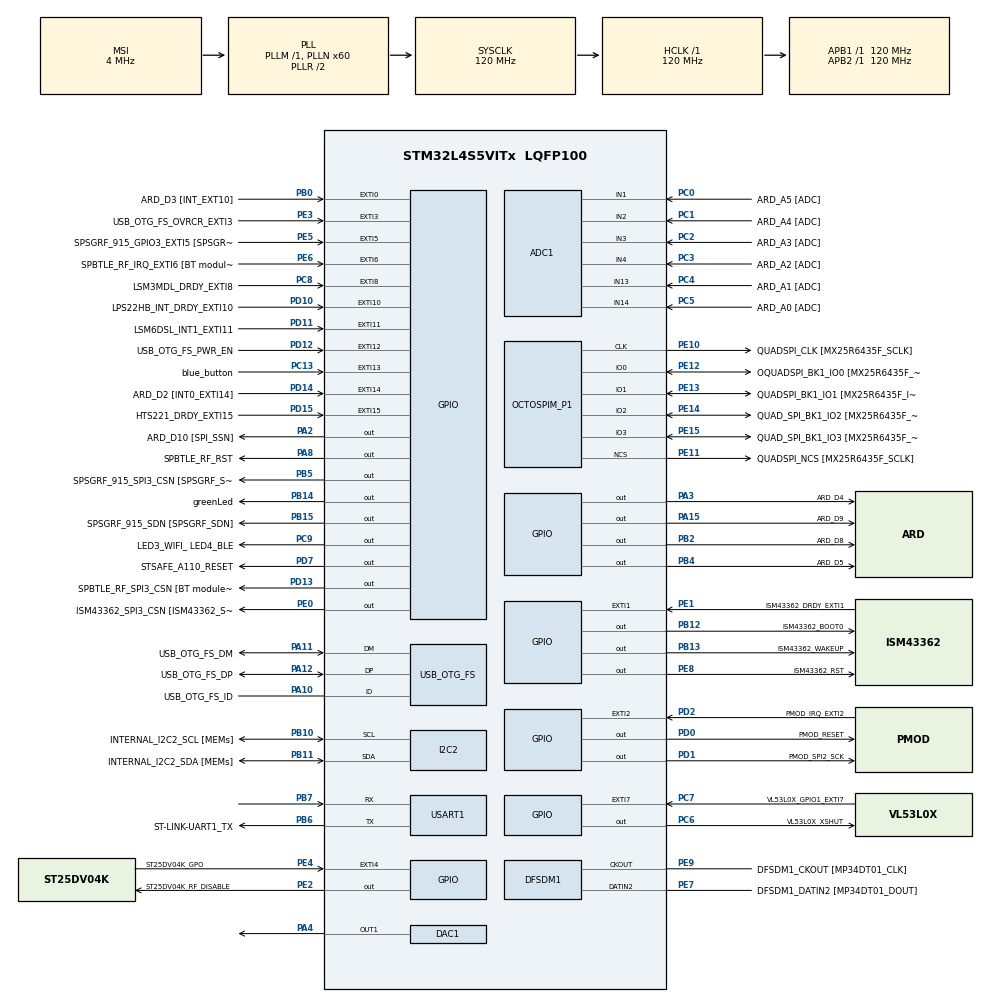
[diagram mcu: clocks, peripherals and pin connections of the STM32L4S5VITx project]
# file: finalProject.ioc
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ADC1.Channel-0\#ChannelRegularConversion=ADC_CHANNEL_1
ADC1.NbrOfConversionFlag=1
ADC1.OffsetNumber-0\#ChannelRegularConversion=ADC_OFFSET_NONE
ADC1.Rank-0\#ChannelRegularConversion=1
ADC1.SamplingTime-0\#ChannelRegularConversion=ADC_SAMPLETIME_2CYCLES_5
ADC1.master=1
DAC1.DAC_Trigger-DAC_OUT1=DAC_TRIGGER_T2_TRGO
Dma.DAC1_CH1.0.Direction=DMA_MEMORY_TO_PERIPH
Dma.DAC1_CH1.0.EventEnable=DISABLE
Dma.DAC1_CH1.0.Instance=DMA1_Channel1
Dma.DAC1_CH1.0.MemDataAlignment=DMA_MDATAALIGN_WORD
Dma.DAC1_CH1.0.MemInc=DMA_MINC_ENABLE
Dma.DAC1_CH1.0.Mode=DMA_CIRCULAR
Dma.DAC1_CH1.0.PeriphDataAlignment=DMA_PDATAALIGN_HALFWORD
Dma.DAC1_CH1.0.PeriphInc=DMA_PINC_DISABLE
Dma.DAC1_CH1.0.Polarity=HAL_DMAMUX_REQUEST_GEN_RISING
Dma.DAC1_CH1.0.Priority=DMA_PRIORITY_LOW
Dma.DAC1_CH1.0.RequestNumber=1
Dma.DAC1_CH1.0.SignalID=NONE
Dma.DAC1_CH1.0.SyncEnable=DISABLE
Dma.DAC1_CH1.0.SyncPolarity=HAL_DMAMUX_SYNC_NO_EVENT
Dma.DAC1_CH1.0.SyncRequestNumber=1
Dma.DAC1_CH1.0.SyncSignalID=NONE
Dma.Request0=DAC1_CH1
I2C2.Timing=0x30A175AB
Mcu.Family=STM32L4
Mcu.Name=STM32L4S5VITx
Mcu.Package=LQFP100
NVIC.DMA1_Channel1_IRQn=true\:0\:0\:false\:false\:true\:false\:true\:true
NVIC.EXTI15_10_IRQn=true\:0\:0\:false\:false\:true\:true\:true\:true
NVIC.EXTI9_5_IRQn=true\:0\:0\:false\:false\:true\:true\:true\:true
NVIC.PriorityGroup=NVIC_PRIORITYGROUP_4
OCTOSPI1.MemoryType=HAL_OSPI_MEMTYPE_MACRONIX
PA0.GPIO_Label=ARD_D1 [UART4_TX]
PA0.GPIO_ModeDefaultPP=GPIO_MODE_AF_PP
PA0.GPIO_PuPd=GPIO_NOPULL
PA0.GPIO_Speed=GPIO_SPEED_FREQ_VERY_HIGH
PA0.Signal=UART4_TX
PA1.GPIO_Label=ARD_D0 [UART4_RX]
PA1.GPIO_ModeDefaultPP=GPIO_MODE_AF_PP
PA1.GPIO_PuPd=GPIO_NOPULL
PA1.GPIO_Speed=GPIO_SPEED_FREQ_VERY_HIGH
PA1.Signal=UART4_RX
PA10.GPIO_Label=USB_OTG_FS_ID
PA10.Mode=OTG/Dual_Role_Device
PA10.Signal=USB_OTG_FS_ID
PA11.GPIO_Label=USB_OTG_FS_DM
PA11.Mode=OTG/Dual_Role_Device
PA11.Signal=USB_OTG_FS_DM
PA12.GPIO_Label=USB_OTG_FS_DP
PA12.Mode=OTG/Dual_Role_Device
PA12.Signal=USB_OTG_FS_DP
PA13\ (JTMS/SWDIO).GPIO_Label=SYS_JTMS_SWDIO
PA13\ (JTMS/SWDIO).Mode=Serial_Wire
PA13\ (JTMS/SWDIO).Signal=SYS_JTMS-SWDIO
PA14\ (JTCK/SWCLK).GPIO_Label=SYS_JTCK_SWCLK
PA14\ (JTCK/SWCLK).Mode=Serial_Wire
PA14\ (JTCK/SWCLK).Signal=SYS_JTCK-SWCLK
PA15\ (JTDI).GPIO_Label=ARD_D9
PA15\ (JTDI).GPIO_ModeDefaultOutputPP=GPIO_MODE_OUTPUT_PP
PA15\ (JTDI).GPIO_PuPd=GPIO_NOPULL
PA15\ (JTDI).GPIO_Speed=GPIO_SPEED_FREQ_LOW
PA15\ (JTDI).PinState=GPIO_PIN_RESET
PA15\ (JTDI).Signal=GPIO_Output
PA2.GPIO_Label=ARD_D10 [SPI_SSN]
PA2.GPIO_ModeDefaultOutputPP=GPIO_MODE_OUTPUT_PP
PA2.GPIO_PuPd=GPIO_NOPULL
PA2.GPIO_Speed=GPIO_SPEED_FREQ_LOW
PA2.PinState=GPIO_PIN_RESET
PA2.Signal=GPIO_Output
PA3.GPIO_Label=ARD_D4
PA3.Signal=GPIO_Output
PA4.Signal=COMP_DAC11_group
PA5.GPIO_Label=ARD_D13 [SPI1_SCK/LED1]
PA5.GPIO_Mode=GPIO_MODE_AF_PP
PA5.GPIO_PuPd=GPIO_NOPULL
PA5.GPIO_Speed=GPIO_SPEED_FREQ_VERY_HIGH
PA5.Signal=SPI1_SCK
PA6.GPIO_Label=ARD_D12 [SPI1_MISO]
PA6.GPIO_Mode=GPIO_MODE_AF_PP
PA6.GPIO_PuPd=GPIO_NOPULL
PA6.GPIO_Speed=GPIO_SPEED_FREQ_VERY_HIGH
PA6.Signal=SPI1_MISO
PA7.GPIO_Label=ARD_D11 [SPI1_MOSI]
PA7.GPIO_Mode=GPIO_MODE_AF_PP
PA7.GPIO_PuPd=GPIO_NOPULL
PA7.GPIO_Speed=GPIO_SPEED_FREQ_VERY_HIGH
PA7.Signal=SPI1_MOSI
PA8.GPIO_Label=SPBTLE_RF_RST
PA8.GPIO_ModeDefaultOutputPP=GPIO_MODE_OUTPUT_PP
PA8.GPIO_PuPd=GPIO_NOPULL
PA8.GPIO_Speed=GPIO_SPEED_FREQ_LOW
PA8.PinState=GPIO_PIN_RESET
PA8.Signal=GPIO_Output
PB0.GPIO_Label=ARD_D3 [INT_EXT10]
PB0.GPIO_ModeDefaultEXTI=GPIO_MODE_IT_RISING
PB0.GPIO_PuPd=GPIO_NOPULL
PB0.Signal=GPXTI0
PB1.GPIO_Label=ARD_D6
PB1.GPIO_Speed=GPIO_SPEED_FREQ_LOW
PB1.Signal=S_TIM3_CH4
PB10.GPIO_Label=INTERNAL_I2C2_SCL [MEMs]
PB10.GPIO_Mode=GPIO_MODE_AF_OD
PB10.GPIO_Pu=GPIO_PULLUP
PB10.GPIO_Speed=GPIO_SPEED_FREQ_VERY_HIGH
PB10.Mode=I2C
PB10.Signal=I2C2_SCL
PB11.GPIO_Label=INTERNAL_I2C2_SDA [MEMs]
PB11.GPIO_Mode=GPIO_MODE_AF_OD
PB11.GPIO_Pu=GPIO_PULLUP
PB11.GPIO_Speed=GPIO_SPEED_FREQ_VERY_HIGH
PB11.Mode=I2C
PB11.Signal=I2C2_SDA
PB12.GPIO_Label=ISM43362_BOOT0
PB12.GPIO_ModeDefaultOutputPP=GPIO_MODE_OUTPUT_PP
PB12.GPIO_PuPd=GPIO_NOPULL
PB12.GPIO_Speed=GPIO_SPEED_FREQ_LOW
PB12.PinState=GPIO_PIN_RESET
PB12.Signal=GPIO_Output
PB13.GPIO_Label=ISM43362_WAKEUP
PB13.GPIO_ModeDefaultOutputPP=GPIO_MODE_OUTPUT_PP
PB13.GPIO_PuPd=GPIO_NOPULL
PB13.GPIO_Speed=GPIO_SPEED_FREQ_LOW
PB13.PinState=GPIO_PIN_RESET
PB13.Signal=GPIO_Output
PB14.GPIO_Label=greenLed
PB14.GPIO_ModeDefaultOutputPP=GPIO_MODE_OUTPUT_PP
PB14.GPIO_PuPd=GPIO_NOPULL
PB14.GPIO_Speed=GPIO_SPEED_FREQ_LOW
PB14.PinState=GPIO_PIN_RESET
PB14.Signal=GPIO_Output
PB15.GPIO_Label=SPSGRF_915_SDN [SPSGRF_SDN]
PB15.Signal=GPIO_Output
PB2.GPIO_Label=ARD_D8
PB2.GPIO_ModeDefaultOutputPP=GPIO_MODE_OUTPUT_PP
PB2.GPIO_PuPd=GPIO_NOPULL
PB2.GPIO_Speed=GPIO_SPEED_FREQ_LOW
PB2.PinState=GPIO_PIN_RESET
PB2.Signal=GPIO_Output
PB3\ (JTDO/TRACESWO).GPIO_Label=SYS_JTD0_SWO
PB3\ (JTDO/TRACESWO).Signal=SYS_JTDO-SWO
PB4\ (NJTRST).GPIO_Label=ARD_D5
PB4\ (NJTRST).GPIO_ModeDefaultOutputPP=GPIO_MODE_OUTPUT_PP
PB4\ (NJTRST).GPIO_PuPd=GPIO_NOPULL
PB4\ (NJTRST).GPIO_Speed=GPIO_SPEED_FREQ_LOW
PB4\ (NJTRST).PinState=GPIO_PIN_RESET
PB4\ (NJTRST).Signal=GPIO_Output
PB5.GPIO_Label=SPSGRF_915_SPI3_CSN [SPSGRF_SPI_CS]
PB5.Signal=GPIO_Output
PB6.GPIO_FM6=__NULL
PB6.GPIO_Label=ST-LINK-UART1_TX
PB6.GPIO_ModeDefaultPP=GPIO_MODE_AF_PP
PB6.GPIO_PuPd=GPIO_NOPULL
PB6.GPIO_Speed=GPIO_SPEED_FREQ_VERY_HIGH
PB6.Mode=Asynchronous
PB6.Signal=USART1_TX
PB7.Mode=Asynchronous
PB7.Signal=USART1_RX
PB8.GPIO_FM8=__NULL
PB8.GPIO_Label=ARD_D15 [I2C1_SCL]
PB8.GPIO_Mode=GPIO_MODE_AF_OD
PB8.GPIO_Pu=GPIO_PULLUP
PB8.GPIO_Speed=GPIO_SPEED_FREQ_VERY_HIGH
PB8.Signal=I2C1_SCL
PB9.GPIO_FM9=__NULL
PB9.GPIO_Label=ARD_D14 [I2C1_SDA]
PB9.GPIO_Mode=GPIO_MODE_AF_OD
PB9.GPIO_Pu=GPIO_PULLUP
PB9.GPIO_Speed=GPIO_SPEED_FREQ_VERY_HIGH
PB9.Signal=I2C1_SDA
PC0.GPIO_Label=ARD_A5 [ADC]
PC0.GPIO_Mode=GPIO_MODE_ANALOG_ADC_CONTROL
PC0.GPIO_PuPd=GPIO_NOPULL
PC0.Signal=ADCx_IN1
PC1.GPIO_Label=ARD_A4 [ADC]
PC1.GPIO_Mode=GPIO_MODE_ANALOG_ADC_CONTROL
PC1.GPIO_PuPd=GPIO_NOPULL
PC1.Signal=ADCx_IN2
PC10.GPIO_Label=INTERNAL-SPI3_SCK [BT module_SPI_MOSI] [ISM43362_MOSI]
PC10.GPIO_Mode=GPIO_MODE_AF_PP
PC10.GPIO_PuPd=GPIO_NOPULL
PC10.GPIO_Speed=GPIO_SPEED_FREQ_VERY_HIGH
PC10.Signal=SPI3_SCK
PC11.GPIO_Label=INTERNAL_SPI3_MISO [BT module_SPI_MOSI] [ISM43362_MOSI]
PC11.GPIO_Mode=GPIO_MODE_AF_PP
PC11.GPIO_PuPd=GPIO_NOPULL
PC11.GPIO_Speed=GPIO_SPEED_FREQ_VERY_HIGH
PC11.Signal=SPI3_MISO
PC12.GPIO_Label=INTERNAL_SPI3_MOSI [BT module_SPI_MOSI] [ISM43362_MOSI]
PC12.GPIO_Mode=GPIO_MODE_AF_PP
PC12.GPIO_PuPd=GPIO_NOPULL
PC12.GPIO_Speed=GPIO_SPEED_FREQ_VERY_HIGH
PC12.Signal=SPI3_MOSI
PC13.GPIO_Label=blue_button
PC13.Signal=GPXTI13
PC14-OSC32_IN\ (PC14).Mode=LSE-External-Oscillator
PC14-OSC32_IN\ (PC14).Signal=RCC_OSC32_IN
PC15-OSC32_OUT\ (PC15).Mode=LSE-External-Oscillator
PC15-OSC32_OUT\ (PC15).Signal=RCC_OSC32_OUT
PC2.GPIO_Label=ARD_A3 [ADC]
PC2.GPIO_Mode=GPIO_MODE_ANALOG_ADC_CONTROL
PC2.GPIO_PuPd=GPIO_NOPULL
PC2.Signal=ADCx_IN3
PC3.GPIO_Label=ARD_A2 [ADC]
PC3.GPIO_Mode=GPIO_MODE_ANALOG_ADC_CONTROL
PC3.GPIO_PuPd=GPIO_NOPULL
PC3.Signal=ADCx_IN4
PC4.GPIO_Label=ARD_A1 [ADC]
PC4.GPIO_Mode=GPIO_MODE_ANALOG_ADC_CONTROL
PC4.GPIO_PuPd=GPIO_NOPULL
PC4.Signal=ADCx_IN13
PC5.GPIO_Label=ARD_A0 [ADC]
PC5.GPIO_Mode=GPIO_MODE_ANALOG_ADC_CONTROL
PC5.GPIO_PuPd=GPIO_NOPULL
PC5.Signal=ADCx_IN14
PC6.GPIO_Label=VL53L0X_XSHUT
PC6.GPIO_ModeDefaultOutputPP=GPIO_MODE_OUTPUT_PP
PC6.GPIO_PuPd=GPIO_NOPULL
PC6.GPIO_Speed=GPIO_SPEED_FREQ_LOW
PC6.PinState=GPIO_PIN_RESET
PC6.Signal=GPIO_Output
PC7.GPIO_Label=VL53L0X_GPIO1_EXTI7
PC7.GPIO_ModeDefaultEXTI=GPIO_MODE_IT_RISING
PC7.GPIO_PuPd=GPIO_NOPULL
PC7.Signal=GPXTI7
PC8.GPIO_Label=LSM3MDL_DRDY_EXTI8
PC8.GPIO_ModeDefaultEXTI=GPIO_MODE_IT_RISING
PC8.GPIO_PuPd=GPIO_NOPULL
PC8.Signal=GPXTI8
PC9.GPIO_Label=LED3_WIFI_ LED4_BLE
PC9.GPIO_ModeDefaultOutputPP=GPIO_MODE_OUTPUT_PP
PC9.GPIO_PuPd=GPIO_NOPULL
PC9.GPIO_Speed=GPIO_SPEED_FREQ_LOW
PC9.PinState=GPIO_PIN_RESET
PC9.Signal=GPIO_Output
PD0.GPIO_Label=PMOD_RESET
PD0.GPIO_ModeDefaultOutputPP=GPIO_MODE_OUTPUT_PP
PD0.GPIO_PuPd=GPIO_NOPULL
PD0.GPIO_Speed=GPIO_SPEED_FREQ_LOW
PD0.PinState=GPIO_PIN_RESET
PD0.Signal=GPIO_Output
PD1.GPIO_Label=PMOD_SPI2_SCK
PD1.Signal=GPIO_Output
PD10.GPIO_Label=LPS22HB_INT_DRDY_EXTI10
PD10.GPIO_ModeDefaultEXTI=GPIO_MODE_IT_RISING
PD10.GPIO_PuPd=GPIO_NOPULL
PD10.Signal=GPXTI10
PD11.GPIO_Label=LSM6DSL_INT1_EXTI11
PD11.GPIO_ModeDefaultEXTI=GPIO_MODE_IT_RISING
PD11.GPIO_PuPd=GPIO_NOPULL
PD11.Signal=GPXTI11
PD12.GPIO_Label=USB_OTG_FS_PWR_EN
PD12.GPIO_ModeDefaultEXTI=GPIO_MODE_IT_RISING
PD12.GPIO_PuPd=GPIO_NOPULL
PD12.Signal=GPXTI12
PD13.GPIO_Label=SPBTLE_RF_SPI3_CSN [BT module_SPI_CS]
PD13.GPIO_ModeDefaultOutputPP=GPIO_MODE_OUTPUT_PP
PD13.GPIO_PuPd=GPIO_NOPULL
PD13.GPIO_Speed=GPIO_SPEED_FREQ_LOW
PD13.PinState=GPIO_PIN_RESET
PD13.Signal=GPIO_Output
PD14.GPIO_Label=ARD_D2 [INT0_EXTI14]
PD14.GPIO_ModeDefaultEXTI=GPIO_MODE_IT_RISING
PD14.GPIO_PuPd=GPIO_NOPULL
PD14.Signal=GPXTI14
PD15.GPIO_Label=HTS221_DRDY_EXTI15
PD15.GPIO_ModeDefaultEXTI=GPIO_MODE_IT_RISING
PD15.GPIO_PuPd=GPIO_NOPULL
PD15.Signal=GPXTI15
PD2.GPIO_Label=PMOD_IRQ_EXTI2
PD2.GPIO_ModeDefaultEXTI=GPIO_MODE_IT_RISING
PD2.GPIO_PuPd=GPIO_NOPULL
PD2.Signal=GPXTI2
PD3.GPIO_Label=PMOD_UART2_CTS
PD3.GPIO_Mode=GPIO_MODE_AF_PP
PD3.GPIO_PuPd=GPIO_NOPULL
PD3.GPIO_Speed=GPIO_SPEED_FREQ_VERY_HIGH
PD3.Signal=USART2_CTS
PD4.GPIO_Label=PMOD_UART2_RTS
PD4.GPIO_Mode=GPIO_MODE_AF_PP
PD4.GPIO_PuPd=GPIO_NOPULL
PD4.GPIO_Speed=GPIO_SPEED_FREQ_VERY_HIGH
PD4.Signal=USART2_RTS
PD5.GPIO_Label=PMOD_UART2_TX
PD5.GPIO_ModeDefaultPP=GPIO_MODE_AF_PP
PD5.GPIO_PuPd=GPIO_NOPULL
PD5.GPIO_Speed=GPIO_SPEED_FREQ_VERY_HIGH
PD5.Signal=USART2_TX
PD6.GPIO_Label=PMOD_UART2_RX
PD6.GPIO_ModeDefaultPP=GPIO_MODE_AF_PP
PD6.GPIO_PuPd=GPIO_NOPULL
PD6.GPIO_Speed=GPIO_SPEED_FREQ_VERY_HIGH
PD6.Signal=USART2_RX
PD7.GPIO_Label=STSAFE_A110_RESET
PD7.GPIO_ModeDefaultOutputPP=GPIO_MODE_OUTPUT_PP
PD7.GPIO_PuPd=GPIO_NOPULL
PD7.GPIO_Speed=GPIO_SPEED_FREQ_LOW
PD7.PinState=GPIO_PIN_RESET
PD7.Signal=GPIO_Output
PD8.GPIO_Label=INTERNAL_UART3_TX [ISM43362_RX]
PD8.GPIO_ModeDefaultPP=GPIO_MODE_AF_PP
PD8.GPIO_PuPd=GPIO_NOPULL
PD8.GPIO_Speed=GPIO_SPEED_FREQ_VERY_HIGH
PD8.Signal=USART3_TX
PD9.GPIO_Label=INTERNAL_UART3_RX [ISM43362_TX]
PD9.GPIO_ModeDefaultPP=GPIO_MODE_AF_PP
PD9.GPIO_PuPd=GPIO_NOPULL
PD9.GPIO_Speed=GPIO_SPEED_FREQ_VERY_HIGH
PD9.Signal=USART3_RX
PE0.GPIO_Label=ISM43362_SPI3_CSN [ISM43362_SSN]
PE0.GPIO_ModeDefaultOutputPP=GPIO_MODE_OUTPUT_PP
PE0.GPIO_PuPd=GPIO_NOPULL
PE0.GPIO_Speed=GPIO_SPEED_FREQ_LOW
PE0.PinState=GPIO_PIN_RESET
PE0.Signal=GPIO_Output
PE1.GPIO_Label=ISM43362_DRDY_EXTI1
PE1.GPIO_ModeDefaultEXTI=GPIO_MODE_IT_RISING
PE1.GPIO_PuPd=GPIO_NOPULL
PE1.Signal=GPXTI1
PE10.GPIO_Label=QUADSPI_CLK [MX25R6435F_SCLK]
PE10.GPIO_Mode=GPIO_MODE_AF_PP
PE10.GPIO_PuPd=GPIO_NOPULL
PE10.GPIO_Speed_High_Default=GPIO_SPEED_FREQ_VERY_HIGH
PE10.Mode=O1_P1_CLK
PE10.Signal=OCTOSPIM_P1_CLK
PE11.GPIO_Label=QUADSPI_NCS [MX25R6435F_SCLK]
PE11.GPIO_Mode=GPIO_MODE_AF_PP
PE11.GPIO_PuPd=GPIO_NOPULL
PE11.GPIO_Speed_High_Default=GPIO_SPEED_FREQ_VERY_HIGH
PE11.Mode=OCTOSPI1_Port1_NCS
PE11.Signal=OCTOSPIM_P1_NCS
PE12.GPIO_Label=OQUADSPI_BK1_IO0 [MX25R6435F_IO0]
PE12.GPIO_Mode=GPIO_MODE_AF_PP
PE12.GPIO_PuPd=GPIO_NOPULL
PE12.GPIO_Speed_High_Default=GPIO_SPEED_FREQ_VERY_HIGH
PE12.Mode=OCTOSPI1_IOL_Port1L
PE12.Signal=OCTOSPIM_P1_IO0
PE13.GPIO_Label=QUADSPI_BK1_IO1 [MX25R6435F_IO1]
PE13.GPIO_Mode=GPIO_MODE_AF_PP
PE13.GPIO_PuPd=GPIO_NOPULL
PE13.GPIO_Speed_High_Default=GPIO_SPEED_FREQ_VERY_HIGH
PE13.Mode=OCTOSPI1_IOL_Port1L
PE13.Signal=OCTOSPIM_P1_IO1
PE14.GPIO_Label=QUAD_SPI_BK1_IO2 [MX25R6435F_IO2]
PE14.GPIO_Mode=GPIO_MODE_AF_PP
PE14.GPIO_PuPd=GPIO_NOPULL
PE14.GPIO_Speed_High_Default=GPIO_SPEED_FREQ_VERY_HIGH
PE14.Mode=OCTOSPI1_IOL_Port1L
PE14.Signal=OCTOSPIM_P1_IO2
PE15.GPIO_Label=QUAD_SPI_BK1_IO3 [MX25R6435F_IO3]
PE15.GPIO_Mode=GPIO_MODE_AF_PP
PE15.GPIO_PuPd=GPIO_NOPULL
PE15.GPIO_Speed_High_Default=GPIO_SPEED_FREQ_VERY_HIGH
PE15.Mode=OCTOSPI1_IOL_Port1L
PE15.Signal=OCTOSPIM_P1_IO3
PE2.GPIO_Label=ST25DV04K_RF_DISABLE
PE2.GPIO_ModeDefaultOutputPP=GPIO_MODE_OUTPUT_PP
PE2.GPIO_PuPd=GPIO_NOPULL
PE2.GPIO_Speed=GPIO_SPEED_FREQ_LOW
PE2.PinState=GPIO_PIN_RESET
PE2.Signal=GPIO_Output
PE3.GPIO_Label=USB_OTG_FS_OVRCR_EXTI3
PE3.GPIO_ModeDefaultEXTI=GPIO_MODE_IT_RISING
PE3.GPIO_PuPd=GPIO_NOPULL
PE3.Signal=GPXTI3
PE4.GPIO_Label=ST25DV04K_GPO
PE4.GPIO_ModeDefaultEXTI=GPIO_MODE_IT_RISING
PE4.GPIO_PuPd=GPIO_NOPULL
PE4.Signal=GPXTI4
PE5.GPIO_Label=SPSGRF_915_GPIO3_EXTI5 [SPSGRF_GPIO_3]
PE5.Signal=GPXTI5
PE6.GPIO_Label=SPBTLE_RF_IRQ_EXTI6 [BT module_SPI_IRQ]
PE6.GPIO_ModeDefaultEXTI=GPIO_MODE_IT_RISING
PE6.GPIO_PuPd=GPIO_NOPULL
PE6.Signal=GPXTI6
PE7.GPIO_Label=DFSDM1_DATIN2 [MP34DT01_DOUT]
PE7.GPIO_Mode=GPIO_MODE_AF_PP
PE7.GPIO_PuPd=GPIO_NOPULL
PE7.GPIO_Speed=GPIO_SPEED_FREQ_LOW
PE7.Signal=S_DATAIN2DFSDM1
PE8.GPIO_Label=ISM43362_RST
PE8.GPIO_ModeDefaultOutputPP=GPIO_MODE_OUTPUT_PP
PE8.GPIO_PuPd=GPIO_NOPULL
PE8.GPIO_Speed=GPIO_SPEED_FREQ_LOW
PE8.PinState=GPIO_PIN_RESET
PE8.Signal=GPIO_Output
PE9.GPIO_Label=DFSDM1_CKOUT [MP34DT01_CLK]
PE9.GPIO_Mode=GPIO_MODE_AF_PP
PE9.GPIO_PuPd=GPIO_NOPULL
PE9.GPIO_Speed=GPIO_SPEED_FREQ_LOW
PE9.Signal=S_CKOUTDFSDM1
PH0-OSC_IN\ (PH0).Mode=HSE-External-Oscillator
PH0-OSC_IN\ (PH0).Signal=RCC_OSC_IN
PH1-OSC_OUT\ (PH1).Mode=HSE-External-Oscillator
PH1-OSC_OUT\ (PH1).Signal=RCC_OSC_OUT
ProjectManager.HeapSize=0x200
ProjectManager.StackSize=0x400
ProjectManager.TargetToolchain=STM32CubeIDE
RCC.ADCFreq_Value=48000000
RCC.AHBFreq_Value=120000000
RCC.APB1Freq_Value=120000000
RCC.APB1TimFreq_Value=120000000
RCC.APB2Freq_Value=120000000
RCC.APB2TimFreq_Value=120000000
RCC.CortexFreq_Value=120000000
RCC.HCLKFreq_Value=120000000
RCC.HSE_VALUE=8000000
RCC.HSI48_VALUE=48000000
RCC.HSI_VALUE=16000000
RCC.MSI_VALUE=4000000
RCC.PLLN=60
RCC.PLLSAI1N=24
RCC.SYSCLKFreq_VALUE=120000000
RCC.SYSCLKSource=RCC_SYSCLKSOURCE_PLLCLK
RCC.USBFreq_Value=48000000
RCC.VCOOutputFreq_Value=240000000
SH.ADCx_IN1.0=ADC1_IN1,IN1-Single-Ended
SH.ADCx_IN13.0=ADC1_IN13,IN13-Single-Ended
SH.ADCx_IN14.0=ADC1_IN14,IN14-Single-Ended
SH.ADCx_IN2.0=ADC1_IN2,IN2-Single-Ended
SH.ADCx_IN3.0=ADC1_IN3,IN3-Single-Ended
SH.ADCx_IN4.0=ADC1_IN4,IN4-Single-Ended
SH.COMP_DAC11_group.0=DAC1_OUT1,DAC_OUT1
SH.S_CKOUTDFSDM1.0=DFSDM1_CKOUT,PDM_SPI_input_from_ch2_and_internal_clock
SH.S_DATAIN2DFSDM1.0=DFSDM1_DATIN2,PDM_SPI_input_from_ch2_and_internal_clock
SH.S_TIM3_CH4.0=TIM3_CH4
TIM2.Period=1000
TIM2.TIM_MasterOutputTrigger=TIM_TRGO_UPDATE
USART1.VirtualMode-Asynchronous=VM_ASYNC
VP_OCTOSPI1_VS_quad.Mode=quad_mode
VP_TIM2_VS_ClockSourceINT.Mode=Internal
board=B-L4S5I-IOT01A

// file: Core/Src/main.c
/* USER CODE BEGIN Header */
/**
  ******************************************************************************
  * @file           : main.c
  * @brief          : Main program body
  ******************************************************************************
  * @attention
  *
  * Copyright (c) 2025 STMicroelectronics.
  * All rights reserved.
  *
  * This software is licensed under terms that can be found in the LICENSE file
  * in the root directory of this software component.
  * If no LICENSE file comes with this software, it is provided AS-IS.
  *
  ******************************************************************************
  */
/* USER CODE END Header */
#include "main.h"

/* USER CODE BEGIN Includes */
#include <math.h>
#define ARM_MATH_CM4
#include <stdio.h>
#include <stdbool.h>
#include "stm32l4s5i_iot01_accelero.h"
#include "stm32l4s5i_iot01.h"
#include <string.h>
/* USER CODE END Includes */

/* USER CODE BEGIN PTD */
#define ITM_STIMULUS_PORT0 (*(volatile uint32_t *)0xE0000000)
/* USER CODE END PTD */

ADC_HandleTypeDef hadc1;

DAC_HandleTypeDef hdac1;
DMA_HandleTypeDef hdma_dac1_ch1;

DFSDM_Channel_HandleTypeDef hdfsdm1_channel2;

I2C_HandleTypeDef hi2c2;

OSPI_HandleTypeDef hospi1;

TIM_HandleTypeDef htim2;

UART_HandleTypeDef huart1;

/* USER CODE BEGIN PV */
// Define application states
typedef enum {
  STATE_IDLE,           // Waiting for shake to begin
  STATE_SHAKING,        // Currently detecting shaking
  STATE_TEMPERATURE,    // Reading temperature for 5 seconds
  STATE_VERIFY          // Verifying the readings
} AppState;

// Parameters for shake detection
#define SHAKE_THRESHOLD     500    // Minimum acceleration change to qualify as shake (reduced from 8000)
#define SHAKE_WINDOW_SIZE   10      // Number of samples to keep for shake detection
#define MIN_SHAKE_COUNT     3       // Number of shakes needed to qualify as "true shake" (reduced from 5)
#define TEMP_MEASURE_TIME   10000    // Temperature measurement time in ms

// Variables for shake detection
int16_t prev_acc[3] = {0, 0, 0};         // Previous accelerometer readings
uint32_t shake_time_start = 0;           // When shaking started
uint8_t shake_count = 0;                 // Counter for actual shakes
uint32_t temp_reading_start = 0;         // When temperature reading started
AppState current_state = STATE_IDLE;     // Current application state

// Variables for temperature verification
float temp_readings[10] = {0};            // Store multiple temperature readings
uint8_t temp_reading_index = 0;          // Current temperature reading index

// Kalman filter state for temperature readings
struct kalman_state temp_kalman = {
    .q = 0.01f,   // Process noise covariance
    .r = 0.5f,    // Measurement noise covariance
    .x = 25.0f,   // Initial estimate (room temperature)
    .p = 1.0f,    // Initial error estimate
    .k = 0.0f     // Initial Kalman gain
};

// For temperature change detection
float baseline_temp = 0.0f;  // Baseline temperature

// DAC audio variables
#define SINE_SAMPLES 32
uint16_t sine_wave[SINE_SAMPLES] = {
    2048, 2448, 2832, 3186, 3496, 3751, 3940, 4056,
    4095, 4056, 3940, 3751, 3496, 3186, 2832, 2448,
    2048, 1648, 1264, 910,  600,  345,  156,  40,
    0,    40,   156,  345,  600,  910,  1264, 1648
};

// Sound frequencies in Hz
#define NOTE_C4  262
#define NOTE_D4  294
#define NOTE_E4  330
#define NOTE_F4  349
#define NOTE_G4  392
#define NOTE_A4  440
#define NOTE_B4  494
#define NOTE_C5  523

// Additional definitions for octave 3 (one octave lower than C4)
#define NOTE_C3  131
#define NOTE_D3  147
#define NOTE_E3  165
#define NOTE_F3  175
#define NOTE_G3  196

// Audio status flag
volatile uint8_t audio_playing = 0;
/* USER CODE END PV */

void SystemClock_Config(void);
void PeriphCommonClock_Config(void);
static void MX_GPIO_Init(void);
static void MX_DMA_Init(void);
static void MX_ADC1_Init(void);
static void MX_DFSDM1_Init(void);
static void MX_OCTOSPI1_Init(void);
static void MX_USART1_UART_Init(void);
static void MX_USB_OTG_FS_USB_Init(void);
static void MX_I2C2_Init(void);
static void MX_DAC1_Init(void);
static void MX_TIM2_Init(void);
/* USER CODE BEGIN PFP */
void change_channel(int i);
bool detect_shake(int16_t* acc);
void blink_led(uint32_t times, uint32_t delay_ms);
void play_shake_detected_sound(void);
void play_countdown_sound(uint32_t seconds_remaining);
void play_success_sound(void);
void update_state_machine(float current_temp);
/* USER CODE END PFP */

/* USER CODE BEGIN 0 */
#define V_REFINT ((uint16_t*)(uint32_t)0x1FFF75AA)
#define TS_CAL1 ((uint16_t*)(uint32_t)0x1FFF75A8)
#define TS_CAL2 ((uint16_t*)(uint32_t)0x1FFF75CA)
#define TS_CAL1_TEMP ((float)30.0)
#define TS_CAL2_TEMP ((float) 130.0)

// Function to detect shaking motion
bool detect_shake(int16_t* acc) {
  // Calculate absolute differences from previous reading
  int32_t delta_x = abs((int32_t)acc[0] - (int32_t)prev_acc[0]);
  int32_t delta_y = abs((int32_t)acc[1] - (int32_t)prev_acc[1]);
  int32_t delta_z = abs((int32_t)acc[2] - (int32_t)prev_acc[2]);

//  // Debug every 500ms (controlled by external timer)
//  static uint32_t last_debug = 0;
//  uint32_t now = HAL_GetTick();
//  if (now - last_debug > 500) {
//    printf("Delta values: x=%ld, y=%ld, z=%ld (threshold: %d)\n",
//           delta_x, delta_y, delta_z, SHAKE_THRESHOLD);
//    last_debug = now;
//  }

  // Save current values as previous for next time
  prev_acc[0] = acc[0];
  prev_acc[1] = acc[1];
  prev_acc[2] = acc[2];

  // Look for rapid movement on at least one axis (changed from two axes)
  int movement_axes = 0;
  if (delta_x > SHAKE_THRESHOLD) movement_axes++;
  if (delta_y > SHAKE_THRESHOLD) movement_axes++;
  if (delta_z > SHAKE_THRESHOLD) movement_axes++;

  return (movement_axes >= 1);  // True if significant movement on at least 1 axis (changed from 2)
}

// Function to blink LED for visual feedback
void blink_led(uint32_t times, uint32_t delay_ms) {
  for (uint32_t i = 0; i < times; i++) {
    HAL_GPIO_WritePin(GPIOB, greenLed_Pin, GPIO_PIN_SET);
    HAL_Delay(delay_ms);
    HAL_GPIO_WritePin(GPIOB, greenLed_Pin, GPIO_PIN_RESET);
    HAL_Delay(delay_ms);
  }
}

void play_tone(uint16_t frequency, uint32_t duration_ms) {
    // Stop any ongoing playback
    if (audio_playing) {
        HAL_DAC_Stop_DMA(&hdac1, DAC_CHANNEL_1);
        audio_playing = 0;
        HAL_Delay(5); // Small delay
    }
    printf("Playing tone: %d Hz for %lu ms\n", frequency, duration_ms);

    // Calculate correct timer clock frequency.
    uint32_t tim_clk = HAL_RCC_GetPCLK1Freq();
    // If APB1 prescaler is not 1, the timer clock is doubled.
    if ((RCC->CFGR & RCC_CFGR_PPRE1) != RCC_CFGR_PPRE1_DIV1) {
        tim_clk *= 2;
    }

    uint32_t timer_period = tim_clk / (frequency * SINE_SAMPLES);
    htim2.Instance->ARR = timer_period - 1;
    htim2.Instance->PSC = 0;

    // Reset timer counter before starting
    __HAL_TIM_SET_COUNTER(&htim2, 0);

    // Start the timer and DAC DMA
    HAL_TIM_Base_Start(&htim2);
    audio_playing = 1;
    HAL_DAC_Start_DMA(&hdac1, DAC_CHANNEL_1, (uint32_t*)sine_wave, SINE_SAMPLES, DAC_ALIGN_12B_R);

    // Allow the tone to play for the duration specified
    HAL_Delay(duration_ms);

    // Stop the DAC DMA and timer
    HAL_DAC_Stop_DMA(&hdac1, DAC_CHANNEL_1);
    HAL_TIM_Base_Stop(&htim2);
    audio_playing = 0;
}

// Add a function to forcibly stop audio
void stop_audio() {
    if (audio_playing) {
        HAL_DAC_Stop_DMA(&hdac1, DAC_CHANNEL_1);
        HAL_TIM_Base_Stop(&htim2);
        audio_playing = 0;
    }
}

// This function is called for audio feedback when a shake is detected
void play_shake_detected_sound(void) {
    stop_audio();
    // Rising tone pattern to indicate shake detection
    play_tone(NOTE_C4, 100);
    play_tone(NOTE_E4, 100);
    play_tone(NOTE_G4, 100);
    play_tone(NOTE_C5, 200);

    // Still blink LED for visual feedback
    blink_led(1, 50);
    stop_audio();

}

// This function is called for audio countdown during temperature reading
void play_countdown_sound(uint32_t seconds_remaining) {
    stop_audio();
    // Different tones based on seconds remaining
    switch(seconds_remaining) {
        case 10:
            play_tone(NOTE_C3, 100);
            break;
        case 9:
            play_tone(NOTE_D3, 100);
            break;
        case 8:
            play_tone(NOTE_E3, 100);
            break;
        case 7:
            play_tone(NOTE_F3, 100);
            break;
        case 6:
            play_tone(NOTE_G3, 100);
            break;
        case 5:
            play_tone(NOTE_C4, 100);
            break;
        case 4:
            play_tone(NOTE_D4, 100);
            break;
        case 3:
            play_tone(NOTE_E4, 100);
            break;
        case 2:
            play_tone(NOTE_G4, 100);
            break;
        case 1:
            play_tone(NOTE_A4, 100);
            break;
        default:
            play_tone(NOTE_C4, 50);
            break;
    }

    // Still blink LED for visual feedback
    blink_led(1, 50);
    HAL_Delay(100);
    stop_audio();
}

// This function is called for temperature reading success
void play_success_sound(void) {
    stop_audio();
    // Success melody
    play_tone(NOTE_C4, 100);
    play_tone(NOTE_E4, 100);
    play_tone(NOTE_G4, 100);
    play_tone(NOTE_C5, 200);
    play_tone(NOTE_G4, 100);
    play_tone(NOTE_C5, 300);

    // Still blink LED for visual feedback
    blink_led(1, 50);
    HAL_Delay(100);
    stop_audio();
}

// This function is called for temperature reading success
void play_fail_sound(void) {
    stop_audio();

    // Failure melody: descending tones to indicate an error
    play_tone(NOTE_C5, 100);
    play_tone(NOTE_B4, 100);
    play_tone(NOTE_A4, 100);
    play_tone(NOTE_G4, 200);
    play_tone(NOTE_F4, 200);
    play_tone(NOTE_E4, 300);

    // Blink LED for visual error indication
    blink_led(2, 50);  // Blinks the LED twice with 50 ms per blink
    HAL_Delay(100);

    stop_audio();
}

// Function to process state machine
void update_state_machine(float current_temp) {
  uint32_t current_time = HAL_GetTick();

  switch (current_state) {
    case STATE_IDLE:
      // In idle state, waiting for shake to be detected
      HAL_GPIO_WritePin(GPIOB, greenLed_Pin, GPIO_PIN_RESET);
      stop_audio();
      shake_count = 0;
      break;

    case STATE_SHAKING:
      // Detecting continuous shaking
      HAL_GPIO_WritePin(GPIOB, greenLed_Pin, GPIO_PIN_SET);

      // If user has been shaking for too long without qualifying, reset
      if (current_time - shake_time_start > 3000 && shake_count < MIN_SHAKE_COUNT) {
        current_state = STATE_IDLE;
        shake_count = 0;
        printf("Shake timeout - please try again\n");
        blink_led(2, 200); // Error indication
      }
      // If enough shakes detected, move to temperature reading
      else if (shake_count >= MIN_SHAKE_COUNT) {
        current_state = STATE_TEMPERATURE;
        temp_reading_start = current_time;
        temp_reading_index = 0;
        printf("Shake detected! Please place finger on temperature sensor\n");
        stop_audio();
        play_shake_detected_sound(); // Audio feedback
      }
      break;

    case STATE_TEMPERATURE:
        // Reading temperature for 5 seconds
        HAL_GPIO_WritePin(GPIOB, greenLed_Pin, GPIO_PIN_SET);

        uint32_t elapsed = current_time - temp_reading_start;
        uint32_t seconds_remaining = (TEMP_MEASURE_TIME - elapsed) / 1000;

        // Capture baseline temperature right at the start
        if (temp_reading_index == 0) {
            baseline_temp = current_temp;
            printf("Baseline temperature: %.2f C\n", baseline_temp);
        }

        if (seconds_remaining < 10 && seconds_remaining >= 0) {
            // Every second, update the countdown
            static uint32_t last_second = 0;
            if (last_second != seconds_remaining) {
                last_second = seconds_remaining;
                printf("Temperature reading: %d seconds remaining\n", (int)seconds_remaining + 1);
                play_countdown_sound(seconds_remaining + 1);

                // Store temperature reading
                if (temp_reading_index < 10) {
                    // Store the temperature value
                    temp_readings[temp_reading_index++] = current_temp;
                    printf("Current temperature: %.2f C (delta: %.2f C)\n",
                           current_temp, current_temp - baseline_temp);
                }
            }
        }

        // When time is up, move to verification
        if (elapsed >= TEMP_MEASURE_TIME) {
            current_state = STATE_VERIFY;
            printf("Temperature reading complete, verifying...\n");
        }
        break;

    case STATE_VERIFY:
        // Process the collected temperature data
        float max_temp = -100.0f;
        float min_temp = 100.0f;
        for (int i = 0; i < temp_reading_index; i++) {
            if (temp_readings[i] > max_temp) {
                max_temp = temp_readings[i];
            }
            else if (temp_readings[i] < min_temp){
            	min_temp = temp_readings[i];
            }
        }

        float top_temp_change = max_temp - baseline_temp;
        float min_temp_change = min_temp - baseline_temp;
        printf("Maximum temperature: %.2f C\n", max_temp);
        printf("Top temperature change: %.2f C\n", top_temp_change);

        // Verify based on temperature change (warming from finger)
        if (top_temp_change >= 0.6f) {
            printf("Verification successful! Detected warming of %.2f C\n", top_temp_change);
            play_success_sound();
        } else {
            printf("Verification failed - insufficient temperature change\n");
            printf("Please place your finger near the board's temperature sensor\n");
            blink_led(2, 200); // Error indication
            play_fail_sound();
        }

        stop_audio();
        shake_count = 0;
        temp_reading_index = 0;
        // Return to idle state
        current_state = STATE_IDLE;
        HAL_GPIO_WritePin(GPIOB, greenLed_Pin, GPIO_PIN_RESET);
        BSP_ACCELERO_AccGetXYZ(prev_acc);
        break;
  }
}

int _write(int file, char *ptr, int len)
{
    // Send each character via ITM
    for (int i = 0; i < len; i++)
    {
        ITM_SendChar(*ptr++);
    }
    return len;
}

void change_channel(int i) {
	ADC_ChannelConfTypeDef Config = {0};

	if (i){
		Config.Channel = ADC_CHANNEL_TEMPSENSOR;
	}
	else{
		Config.Channel = ADC_CHANNEL_VREFINT;
	}

	Config.Rank = ADC_REGULAR_RANK_1,
	Config.SamplingTime = ADC_SAMPLETIME_640CYCLES_5,
	Config.SingleDiff = ADC_SINGLE_ENDED,
	Config.OffsetNumber = ADC_OFFSET_NONE,
	Config.Offset = 0;

	if (HAL_ADC_ConfigChannel(&hadc1, &Config) != HAL_OK){
		Error_Handler();
	}
}

int KalmanFilterC(float* InputArray, float* OutputArray, struct kalman_state* kstate, int length) {
    for (int i = 0; i < length; i++) { // Iterate
        kstate->p = kstate->p + kstate->q;
        kstate->k = kstate->p/(kstate->p + kstate->r);
        kstate->x = kstate->x + (kstate->k)*(InputArray[i]-kstate->x);
        kstate->p = (1-kstate->k)*kstate->p;
        OutputArray[i] = kstate->x; // Store in output array
        int a = __get_FPSCR();
        if ((a & 268435456) != 0) { // Check for overflow (fixed parentheses)
            printf("Overflow.");
            while (1){}
        }
    }
    return 0; // Return 0 if successful or get stuck in while loop
}

// Improved temperature reading function with Kalman filtering
float read_temperature(void) {
    float ADC_value;
    float vref_plus;
    float V_temp;
    float temp_readings[10];

    // Take multiple readings for stability
    for (int i = 0; i < 10; i++) {
        // Measure the voltage ref+
        change_channel(0);
        HAL_ADC_Start(&hadc1);
        HAL_ADC_PollForConversion(&hadc1, HAL_MAX_DELAY);
        ADC_value = (float)HAL_ADC_GetValue(&hadc1);
        HAL_ADC_Stop(&hadc1);
        vref_plus = 3.0f * (float)(*V_REFINT)/ADC_value;

        // Small delay between readings
        HAL_Delay(5);

        // Measure temperature
        change_channel(1);
        HAL_ADC_Start(&hadc1);
        HAL_ADC_PollForConversion(&hadc1, HAL_MAX_DELAY);
        V_temp = (float)HAL_ADC_GetValue(&hadc1);
        HAL_ADC_Stop(&hadc1);

        // Calculate temperature
        temp_readings[i] = (((TS_CAL2_TEMP - TS_CAL1_TEMP)/((float)(*TS_CAL2) - (float)(*TS_CAL1))) *
                          ((V_temp * vref_plus/3.0f)-(float)(*TS_CAL1))) + TS_CAL1_TEMP;

        // Check for obviously wrong readings
        if (temp_readings[i] < -10.0f || temp_readings[i] > 100.0f) {
            temp_readings[i] = (i > 0) ? temp_readings[i-1] : 25.0f; // Use previous or default
        }
    }

    // Apply Kalman filter to the readings
    float filtered_readings[10];
    KalmanFilterC(temp_readings, filtered_readings, &temp_kalman, 10);

    // Return the last filtered value (most current)
    return filtered_readings[4];
}

// DAC DMA error callback
void HAL_DAC_DMAErrorCallback(DAC_HandleTypeDef *hdac) {
    // Handle DMA errors
    audio_playing = 0;
    HAL_DAC_Stop_DMA(&hdac1, DAC_CHANNEL_1);
    HAL_TIM_Base_Stop(&htim2);

    // Signal error with LED
    blink_led(5, 50);
}
/* USER CODE END 0 */

int main(void)
{

  /* MCU Configuration--------------------------------------------------------*/

  /* Reset of all peripherals, Initializes the Flash interface and the Systick. */
  HAL_Init();

  /* Configure the system clock */
  SystemClock_Config();

  /* Configure the peripherals common clocks */
  PeriphCommonClock_Config();

  /* Initialize all configured peripherals */
  MX_GPIO_Init();
  MX_DMA_Init();
  MX_ADC1_Init();
  MX_DFSDM1_Init();
  MX_OCTOSPI1_Init();
  MX_USART1_UART_Init();
  MX_USB_OTG_FS_USB_Init();
  MX_I2C2_Init();
  MX_DAC1_Init();
  MX_TIM2_Init();
  /* USER CODE BEGIN 2 */
  //BSP_TSENSOR_Init();
  //BSP_HSENSOR_Init(); //HTS221
  //BSP_MAGNETO_Init(); //LIS3MDL
  // Initialize the accelerometer with default parameters (±2g range)
  BSP_ACCELERO_Init(); //LSM6DSL

  current_state = STATE_IDLE;  // Explicitly set initial state
  shake_count = 0;             // Reset shake count
  temp_reading_index = 0;      // Reset temperature reading index

  // Initialize TIM2 for DAC triggering
  HAL_TIM_Base_Stop(&htim2);

  // Set accelerometer to full scale - this may be required depending on your board
  // The below is a placeholder - you might need to modify based on your specific board API
  // Read current settings, modify only the scale bits, then write back
  // This is just an example - you need to check your board's specific implementation
  // BSP_ACCELERO_Set_FS(LSM6DSL_ACC_FULLSCALE_16G); // Set to ±16g for better sensitivity
  //BSP_GYRO_Init(); //LSM6DSL
  //BSP_PSENSOR_Init(); //LPS22HB

  float temp = 0;
  int16_t acc[3] = {0};
  uint32_t lastPrintTime = 0;

  printf("\n\n--- Multi-factor Biometric Verification System ---\n");
  printf("Shake the device firmly to begin verification\n");

  // Blink LED to indicate system is ready
  blink_led(2, 250);

  // Perform a reading for a baseline
  BSP_ACCELERO_AccGetXYZ(prev_acc);

  /* USER CODE END 2 */

  /* Infinite loop */
  while (1)
  {

    /* USER CODE BEGIN 3 */
    uint32_t currentTime = HAL_GetTick();

    // Read accelerometer data
    BSP_ACCELERO_AccGetXYZ(acc);

    // Process accelerometer data for shake detection
    if (current_state == STATE_IDLE) {
      // In idle state, look for the start of shaking
      if (detect_shake(acc)) {
        // First shake detected, transition to shaking state
        current_state = STATE_SHAKING;
        shake_time_start = currentTime;
        shake_count = 1;
        printf("Possible shake detected, continue shaking...\n");
      }
    }
    else if (current_state == STATE_SHAKING) {
      // Already in shaking state, count additional shakes
      if (detect_shake(acc)) {
        shake_count++;
        printf("Shake count: %d/%d\n", shake_count, MIN_SHAKE_COUNT);
      }
    }

    // Always read temperature when in temperature reading state or for verification
    // Always read temperature when in temperature reading state or for verification
    if (current_state == STATE_TEMPERATURE || current_state == STATE_VERIFY) {
        temp = read_temperature();
    }

    // For debugging in idle mode, print sensor values occasionally
    if ((current_state == STATE_IDLE || current_state == STATE_SHAKING) &&
        currentTime - lastPrintTime > 1000) {

        // Read temperature with Kalman filtering for display
        temp = read_temperature();

        printf("Status: %s | Accelerometer: x=%d, y=%d, z=%d | Temp: %.2f C\n",
               current_state == STATE_IDLE ? "IDLE" : "SHAKING",
               acc[0], acc[1], acc[2], temp);

        lastPrintTime = currentTime;
    }

    // Update the state machine with current temperature
    update_state_machine(temp);

    // Small delay to prevent CPU hogging
    HAL_Delay(10);
  }
  /* USER CODE END 3 */
}

void SystemClock_Config(void)
{
  RCC_OscInitTypeDef RCC_OscInitStruct = {0};
  RCC_ClkInitTypeDef RCC_ClkInitStruct = {0};

  /** Configure the main internal regulator output voltage
  */
  if (HAL_PWREx_ControlVoltageScaling(PWR_REGULATOR_VOLTAGE_SCALE1_BOOST) != HAL_OK)
  {
    Error_Handler();
  }

  /** Configure LSE Drive Capability
  */
  HAL_PWR_EnableBkUpAccess();
  __HAL_RCC_LSEDRIVE_CONFIG(RCC_LSEDRIVE_LOW);

  /** Initializes the RCC Oscillators according to the specified parameters
  * in the RCC_OscInitTypeDef structure.
  */
  RCC_OscInitStruct.OscillatorType = RCC_OSCILLATORTYPE_LSE|RCC_OSCILLATORTYPE_MSI;
  RCC_OscInitStruct.LSEState = RCC_LSE_ON;
  RCC_OscInitStruct.MSIState = RCC_MSI_ON;
  RCC_OscInitStruct.MSICalibrationValue = 0;
  RCC_OscInitStruct.MSIClockRange = RCC_MSIRANGE_6;
  RCC_OscInitStruct.PLL.PLLState = RCC_PLL_ON;
  RCC_OscInitStruct.PLL.PLLSource = RCC_PLLSOURCE_MSI;
  RCC_OscInitStruct.PLL.PLLM = 1;
  RCC_OscInitStruct.PLL.PLLN = 60;
  RCC_OscInitStruct.PLL.PLLP = RCC_PLLP_DIV2;
  RCC_OscInitStruct.PLL.PLLQ = RCC_PLLQ_DIV2;
  RCC_OscInitStruct.PLL.PLLR = RCC_PLLR_DIV2;
  if (HAL_RCC_OscConfig(&RCC_OscInitStruct) != HAL_OK)
  {
    Error_Handler();
  }

  /** Initializes the CPU, AHB and APB buses clocks
  */
  RCC_ClkInitStruct.ClockType = RCC_CLOCKTYPE_HCLK|RCC_CLOCKTYPE_SYSCLK
                              |RCC_CLOCKTYPE_PCLK1|RCC_CLOCKTYPE_PCLK2;
  RCC_ClkInitStruct.SYSCLKSource = RCC_SYSCLKSOURCE_PLLCLK;
  RCC_ClkInitStruct.AHBCLKDivider = RCC_SYSCLK_DIV1;
  RCC_ClkInitStruct.APB1CLKDivider = RCC_HCLK_DIV1;
  RCC_ClkInitStruct.APB2CLKDivider = RCC_HCLK_DIV1;

  if (HAL_RCC_ClockConfig(&RCC_ClkInitStruct, FLASH_LATENCY_5) != HAL_OK)
  {
    Error_Handler();
  }

  /** Enable MSI Auto calibration
  */
  HAL_RCCEx_EnableMSIPLLMode();
}

void PeriphCommonClock_Config(void)
{
  RCC_PeriphCLKInitTypeDef PeriphClkInit = {0};

  /** Initializes the peripherals clock
  */
  PeriphClkInit.PeriphClockSelection = RCC_PERIPHCLK_USB|RCC_PERIPHCLK_ADC;
  PeriphClkInit.AdcClockSelection = RCC_ADCCLKSOURCE_PLLSAI1;
  PeriphClkInit.UsbClockSelection = RCC_USBCLKSOURCE_PLLSAI1;
  PeriphClkInit.PLLSAI1.PLLSAI1Source = RCC_PLLSOURCE_MSI;
  PeriphClkInit.PLLSAI1.PLLSAI1M = 1;
  PeriphClkInit.PLLSAI1.PLLSAI1N = 24;
  PeriphClkInit.PLLSAI1.PLLSAI1P = RCC_PLLP_DIV2;
  PeriphClkInit.PLLSAI1.PLLSAI1Q = RCC_PLLQ_DIV2;
  PeriphClkInit.PLLSAI1.PLLSAI1R = RCC_PLLR_DIV2;
  PeriphClkInit.PLLSAI1.PLLSAI1ClockOut = RCC_PLLSAI1_48M2CLK|RCC_PLLSAI1_ADC1CLK;
  if (HAL_RCCEx_PeriphCLKConfig(&PeriphClkInit) != HAL_OK)
  {
    Error_Handler();
  }
}

static void MX_ADC1_Init(void)
{

  ADC_ChannelConfTypeDef sConfig = {0};

  /** Common config
  */
  hadc1.Instance = ADC1;
  hadc1.Init.ClockPrescaler = ADC_CLOCK_ASYNC_DIV1;
  hadc1.Init.Resolution = ADC_RESOLUTION_12B;
  hadc1.Init.DataAlign = ADC_DATAALIGN_RIGHT;
  hadc1.Init.ScanConvMode = ADC_SCAN_DISABLE;
  hadc1.Init.EOCSelection = ADC_EOC_SINGLE_CONV;
  hadc1.Init.LowPowerAutoWait = DISABLE;
  hadc1.Init.ContinuousConvMode = DISABLE;
  hadc1.Init.NbrOfConversion = 1;
  hadc1.Init.DiscontinuousConvMode = DISABLE;
  hadc1.Init.ExternalTrigConv = ADC_SOFTWARE_START;
  hadc1.Init.ExternalTrigConvEdge = ADC_EXTERNALTRIGCONVEDGE_NONE;
  hadc1.Init.DMAContinuousRequests = DISABLE;
  hadc1.Init.Overrun = ADC_OVR_DATA_PRESERVED;
  hadc1.Init.OversamplingMode = DISABLE;
  if (HAL_ADC_Init(&hadc1) != HAL_OK)
  {
    Error_Handler();
  }

  /** Configure Regular Channel
  */
  sConfig.Channel = ADC_CHANNEL_1;
  sConfig.Rank = ADC_REGULAR_RANK_1;
  sConfig.SamplingTime = ADC_SAMPLETIME_2CYCLES_5;
  sConfig.SingleDiff = ADC_SINGLE_ENDED;
  sConfig.OffsetNumber = ADC_OFFSET_NONE;
  sConfig.Offset = 0;
  if (HAL_ADC_ConfigChannel(&hadc1, &sConfig) != HAL_OK)
  {
    Error_Handler();
  }

}

static void MX_DAC1_Init(void)
{

  DAC_ChannelConfTypeDef sConfig = {0};

  /** DAC Initialization
  */
  hdac1.Instance = DAC1;
  if (HAL_DAC_Init(&hdac1) != HAL_OK)
  {
    Error_Handler();
  }

  /** DAC channel OUT1 config
  */
  sConfig.DAC_SampleAndHold = DAC_SAMPLEANDHOLD_DISABLE;
  sConfig.DAC_Trigger = DAC_TRIGGER_T2_TRGO;
  sConfig.DAC_HighFrequency = DAC_HIGH_FREQUENCY_INTERFACE_MODE_ABOVE_80MHZ;
  sConfig.DAC_OutputBuffer = DAC_OUTPUTBUFFER_ENABLE;
  sConfig.DAC_ConnectOnChipPeripheral = DAC_CHIPCONNECT_DISABLE;
  sConfig.DAC_UserTrimming = DAC_TRIMMING_FACTORY;
  if (HAL_DAC_ConfigChannel(&hdac1, &sConfig, DAC_CHANNEL_1) != HAL_OK)
  {
    Error_Handler();
  }

}

static void MX_DFSDM1_Init(void)
{

  hdfsdm1_channel2.Instance = DFSDM1_Channel2;
  hdfsdm1_channel2.Init.OutputClock.Activation = ENABLE;
  hdfsdm1_channel2.Init.OutputClock.Selection = DFSDM_CHANNEL_OUTPUT_CLOCK_SYSTEM;
  hdfsdm1_channel2.Init.OutputClock.Divider = 2;
  hdfsdm1_channel2.Init.Input.Multiplexer = DFSDM_CHANNEL_EXTERNAL_INPUTS;
  hdfsdm1_channel2.Init.Input.DataPacking = DFSDM_CHANNEL_STANDARD_MODE;
  hdfsdm1_channel2.Init.Input.Pins = DFSDM_CHANNEL_SAME_CHANNEL_PINS;
  hdfsdm1_channel2.Init.SerialInterface.Type = DFSDM_CHANNEL_SPI_RISING;
  hdfsdm1_channel2.Init.SerialInterface.SpiClock = DFSDM_CHANNEL_SPI_CLOCK_INTERNAL;
  hdfsdm1_channel2.Init.Awd.FilterOrder = DFSDM_CHANNEL_FASTSINC_ORDER;
  hdfsdm1_channel2.Init.Awd.Oversampling = 1;
  hdfsdm1_channel2.Init.Offset = 0;
  hdfsdm1_channel2.Init.RightBitShift = 0x00;
  if (HAL_DFSDM_ChannelInit(&hdfsdm1_channel2) != HAL_OK)
  {
    Error_Handler();
  }

}

static void MX_I2C2_Init(void)
{

  hi2c2.Instance = I2C2;
  hi2c2.Init.Timing = 0x30A175AB;
  hi2c2.Init.OwnAddress1 = 0;
  hi2c2.Init.AddressingMode = I2C_ADDRESSINGMODE_7BIT;
  hi2c2.Init.DualAddressMode = I2C_DUALADDRESS_DISABLE;
  hi2c2.Init.OwnAddress2 = 0;
  hi2c2.Init.OwnAddress2Masks = I2C_OA2_NOMASK;
  hi2c2.Init.GeneralCallMode = I2C_GENERALCALL_DISABLE;
  hi2c2.Init.NoStretchMode = I2C_NOSTRETCH_DISABLE;
  if (HAL_I2C_Init(&hi2c2) != HAL_OK)
  {
    Error_Handler();
  }

  /** Configure Analogue filter
  */
  if (HAL_I2CEx_ConfigAnalogFilter(&hi2c2, I2C_ANALOGFILTER_ENABLE) != HAL_OK)
  {
    Error_Handler();
  }

  /** Configure Digital filter
  */
  if (HAL_I2CEx_ConfigDigitalFilter(&hi2c2, 0) != HAL_OK)
  {
    Error_Handler();
  }

}

static void MX_OCTOSPI1_Init(void)
{

  OSPIM_CfgTypeDef OSPIM_Cfg_Struct = {0};

  /* OCTOSPI1 parameter configuration*/
  hospi1.Instance = OCTOSPI1;
  hospi1.Init.FifoThreshold = 1;
  hospi1.Init.DualQuad = HAL_OSPI_DUALQUAD_DISABLE;
  hospi1.Init.MemoryType = HAL_OSPI_MEMTYPE_MACRONIX;
  hospi1.Init.DeviceSize = 32;
  hospi1.Init.ChipSelectHighTime = 1;
  hospi1.Init.FreeRunningClock = HAL_OSPI_FREERUNCLK_DISABLE;
  hospi1.Init.ClockMode = HAL_OSPI_CLOCK_MODE_0;
  hospi1.Init.ClockPrescaler = 1;
  hospi1.Init.SampleShifting = HAL_OSPI_SAMPLE_SHIFTING_NONE;
  hospi1.Init.DelayHoldQuarterCycle = HAL_OSPI_DHQC_DISABLE;
  hospi1.Init.ChipSelectBoundary = 0;
  hospi1.Init.DelayBlockBypass = HAL_OSPI_DELAY_BLOCK_BYPASSED;
  if (HAL_OSPI_Init(&hospi1) != HAL_OK)
  {
    Error_Handler();
  }
  OSPIM_Cfg_Struct.ClkPort = 1;
  OSPIM_Cfg_Struct.NCSPort = 1;
  OSPIM_Cfg_Struct.IOLowPort = HAL_OSPIM_IOPORT_1_LOW;
  if (HAL_OSPIM_Config(&hospi1, &OSPIM_Cfg_Struct, HAL_OSPI_TIMEOUT_DEFAULT_VALUE) != HAL_OK)
  {
    Error_Handler();
  }

}

static void MX_TIM2_Init(void)
{

  TIM_ClockConfigTypeDef sClockSourceConfig = {0};
  TIM_MasterConfigTypeDef sMasterConfig = {0};

  htim2.Instance = TIM2;
  htim2.Init.Prescaler = 0;
  htim2.Init.CounterMode = TIM_COUNTERMODE_UP;
  htim2.Init.Period = 1000;
  htim2.Init.ClockDivision = TIM_CLOCKDIVISION_DIV1;
  htim2.Init.AutoReloadPreload = TIM_AUTORELOAD_PRELOAD_DISABLE;
  if (HAL_TIM_Base_Init(&htim2) != HAL_OK)
  {
    Error_Handler();
  }
  sClockSourceConfig.ClockSource = TIM_CLOCKSOURCE_INTERNAL;
  if (HAL_TIM_ConfigClockSource(&htim2, &sClockSourceConfig) != HAL_OK)
  {
    Error_Handler();
  }
  sMasterConfig.MasterOutputTrigger = TIM_TRGO_UPDATE;
  sMasterConfig.MasterSlaveMode = TIM_MASTERSLAVEMODE_DISABLE;
  if (HAL_TIMEx_MasterConfigSynchronization(&htim2, &sMasterConfig) != HAL_OK)
  {
    Error_Handler();
  }

}

static void MX_USART1_UART_Init(void)
{

  huart1.Instance = USART1;
  huart1.Init.BaudRate = 115200;
  huart1.Init.WordLength = UART_WORDLENGTH_8B;
  huart1.Init.StopBits = UART_STOPBITS_1;
  huart1.Init.Parity = UART_PARITY_NONE;
  huart1.Init.Mode = UART_MODE_TX_RX;
  huart1.Init.HwFlowCtl = UART_HWCONTROL_NONE;
  huart1.Init.OverSampling = UART_OVERSAMPLING_16;
  huart1.Init.OneBitSampling = UART_ONE_BIT_SAMPLE_DISABLE;
  huart1.Init.ClockPrescaler = UART_PRESCALER_DIV1;
  huart1.AdvancedInit.AdvFeatureInit = UART_ADVFEATURE_NO_INIT;
  if (HAL_UART_Init(&huart1) != HAL_OK)
  {
    Error_Handler();
  }
  if (HAL_UARTEx_SetTxFifoThreshold(&huart1, UART_TXFIFO_THRESHOLD_1_8) != HAL_OK)
  {
    Error_Handler();
  }
  if (HAL_UARTEx_SetRxFifoThreshold(&huart1, UART_RXFIFO_THRESHOLD_1_8) != HAL_OK)
  {
    Error_Handler();
  }
  if (HAL_UARTEx_DisableFifoMode(&huart1) != HAL_OK)
  {
    Error_Handler();
  }

}

static void MX_USB_OTG_FS_USB_Init(void)
{

}

static void MX_DMA_Init(void)
{

  /* DMA controller clock enable */
  __HAL_RCC_DMAMUX1_CLK_ENABLE();
  __HAL_RCC_DMA1_CLK_ENABLE();

  /* DMA interrupt init */
  /* DMA1_Channel1_IRQn interrupt configuration */
  HAL_NVIC_SetPriority(DMA1_Channel1_IRQn, 0, 0);
  HAL_NVIC_EnableIRQ(DMA1_Channel1_IRQn);

}

static void MX_GPIO_Init(void)
{
  GPIO_InitTypeDef GPIO_InitStruct = {0};

  /* GPIO Ports Clock Enable */
  __HAL_RCC_GPIOE_CLK_ENABLE();
  __HAL_RCC_GPIOC_CLK_ENABLE();
  __HAL_RCC_GPIOH_CLK_ENABLE();
  __HAL_RCC_GPIOA_CLK_ENABLE();
  __HAL_RCC_GPIOB_CLK_ENABLE();
  __HAL_RCC_GPIOD_CLK_ENABLE();

  /*Configure GPIO pin Output Level */
  HAL_GPIO_WritePin(GPIOE, ST25DV04K_RF_DISABLE_Pin|ISM43362_RST_Pin|ISM43362_SPI3_CSN_Pin, GPIO_PIN_RESET);

  /*Configure GPIO pin Output Level */
  HAL_GPIO_WritePin(GPIOA, ARD_D10_Pin|ARD_D4_Pin|SPBTLE_RF_RST_Pin|ARD_D9_Pin, GPIO_PIN_RESET);

  /*Configure GPIO pin Output Level */
  HAL_GPIO_WritePin(GPIOB, ARD_D8_Pin|ISM43362_BOOT0_Pin|ISM43362_WAKEUP_Pin|greenLed_Pin
                          |SPSGRF_915_SDN_Pin|ARD_D5_Pin|SPSGRF_915_SPI3_CSN_Pin, GPIO_PIN_RESET);

  /*Configure GPIO pin Output Level */
  HAL_GPIO_WritePin(GPIOD, SPBTLE_RF_SPI3_CSN_Pin|PMOD_RESET_Pin|PMOD_SPI2_SCK_Pin|STSAFE_A110_RESET_Pin, GPIO_PIN_RESET);

  /*Configure GPIO pin Output Level */
  HAL_GPIO_WritePin(GPIOC, VL53L0X_XSHUT_Pin|LED3_WIFI__LED4_BLE_Pin, GPIO_PIN_RESET);

  /*Configure GPIO pins : ST25DV04K_RF_DISABLE_Pin ISM43362_RST_Pin ISM43362_SPI3_CSN_Pin */
  GPIO_InitStruct.Pin = ST25DV04K_RF_DISABLE_Pin|ISM43362_RST_Pin|ISM43362_SPI3_CSN_Pin;
  GPIO_InitStruct.Mode = GPIO_MODE_OUTPUT_PP;
  GPIO_InitStruct.Pull = GPIO_NOPULL;
  GPIO_InitStruct.Speed = GPIO_SPEED_FREQ_LOW;
  HAL_GPIO_Init(GPIOE, &GPIO_InitStruct);

  /*Configure GPIO pins : USB_OTG_FS_OVRCR_EXTI3_Pin ST25DV04K_GPO_Pin SPSGRF_915_GPIO3_EXTI5_Pin SPBTLE_RF_IRQ_EXTI6_Pin
                           ISM43362_DRDY_EXTI1_Pin */
  GPIO_InitStruct.Pin = USB_OTG_FS_OVRCR_EXTI3_Pin|ST25DV04K_GPO_Pin|SPSGRF_915_GPIO3_EXTI5_Pin|SPBTLE_RF_IRQ_EXTI6_Pin
                          |ISM43362_DRDY_EXTI1_Pin;
  GPIO_InitStruct.Mode = GPIO_MODE_IT_RISING;
  GPIO_InitStruct.Pull = GPIO_NOPULL;
  HAL_GPIO_Init(GPIOE, &GPIO_InitStruct);

  /*Configure GPIO pins : blue_button_Pin VL53L0X_GPIO1_EXTI7_Pin LSM3MDL_DRDY_EXTI8_Pin */
  GPIO_InitStruct.Pin = blue_button_Pin|VL53L0X_GPIO1_EXTI7_Pin|LSM3MDL_DRDY_EXTI8_Pin;
  GPIO_InitStruct.Mode = GPIO_MODE_IT_RISING;
  GPIO_InitStruct.Pull = GPIO_NOPULL;
  HAL_GPIO_Init(GPIOC, &GPIO_InitStruct);

  /*Configure GPIO pins : ARD_D1_Pin ARD_D0_Pin */
  GPIO_InitStruct.Pin = ARD_D1_Pin|ARD_D0_Pin;
  GPIO_InitStruct.Mode = GPIO_MODE_AF_PP;
  GPIO_InitStruct.Pull = GPIO_NOPULL;
  GPIO_InitStruct.Speed = GPIO_SPEED_FREQ_VERY_HIGH;
  GPIO_InitStruct.Alternate = GPIO_AF8_UART4;
  HAL_GPIO_Init(GPIOA, &GPIO_InitStruct);

  /*Configure GPIO pins : ARD_D10_Pin ARD_D4_Pin SPBTLE_RF_RST_Pin ARD_D9_Pin */
  GPIO_InitStruct.Pin = ARD_D10_Pin|ARD_D4_Pin|SPBTLE_RF_RST_Pin|ARD_D9_Pin;
  GPIO_InitStruct.Mode = GPIO_MODE_OUTPUT_PP;
  GPIO_InitStruct.Pull = GPIO_NOPULL;
  GPIO_InitStruct.Speed = GPIO_SPEED_FREQ_LOW;
  HAL_GPIO_Init(GPIOA, &GPIO_InitStruct);

  /*Configure GPIO pins : ARD_D13_Pin ARD_D12_Pin ARD_D11_Pin */
  GPIO_InitStruct.Pin = ARD_D13_Pin|ARD_D12_Pin|ARD_D11_Pin;
  GPIO_InitStruct.Mode = GPIO_MODE_AF_PP;
  GPIO_InitStruct.Pull = GPIO_NOPULL;
  GPIO_InitStruct.Speed = GPIO_SPEED_FREQ_VERY_HIGH;
  GPIO_InitStruct.Alternate = GPIO_AF5_SPI1;
  HAL_GPIO_Init(GPIOA, &GPIO_InitStruct);

  /*Configure GPIO pin : ARD_D3_Pin */
  GPIO_InitStruct.Pin = ARD_D3_Pin;
  GPIO_InitStruct.Mode = GPIO_MODE_IT_RISING;
  GPIO_InitStruct.Pull = GPIO_NOPULL;
  HAL_GPIO_Init(ARD_D3_GPIO_Port, &GPIO_InitStruct);

  /*Configure GPIO pin : ARD_D6_Pin */
  GPIO_InitStruct.Pin = ARD_D6_Pin;
  GPIO_InitStruct.Mode = GPIO_MODE_AF_PP;
  GPIO_InitStruct.Pull = GPIO_NOPULL;
  GPIO_InitStruct.Speed = GPIO_SPEED_FREQ_LOW;
  GPIO_InitStruct.Alternate = GPIO_AF2_TIM3;
  HAL_GPIO_Init(ARD_D6_GPIO_Port, &GPIO_InitStruct);

  /*Configure GPIO pins : ARD_D8_Pin ISM43362_BOOT0_Pin ISM43362_WAKEUP_Pin greenLed_Pin
                           SPSGRF_915_SDN_Pin ARD_D5_Pin SPSGRF_915_SPI3_CSN_Pin */
  GPIO_InitStruct.Pin = ARD_D8_Pin|ISM43362_BOOT0_Pin|ISM43362_WAKEUP_Pin|greenLed_Pin
                          |SPSGRF_915_SDN_Pin|ARD_D5_Pin|SPSGRF_915_SPI3_CSN_Pin;
  GPIO_InitStruct.Mode = GPIO_MODE_OUTPUT_PP;
  GPIO_InitStruct.Pull = GPIO_NOPULL;
  GPIO_InitStruct.Speed = GPIO_SPEED_FREQ_LOW;
  HAL_GPIO_Init(GPIOB, &GPIO_InitStruct);

  /*Configure GPIO pins : INTERNAL_UART3_TX_Pin INTERNAL_UART3_RX_Pin */
  GPIO_InitStruct.Pin = INTERNAL_UART3_TX_Pin|INTERNAL_UART3_RX_Pin;
  GPIO_InitStruct.Mode = GPIO_MODE_AF_PP;
  GPIO_InitStruct.Pull = GPIO_NOPULL;
  GPIO_InitStruct.Speed = GPIO_SPEED_FREQ_VERY_HIGH;
  GPIO_InitStruct.Alternate = GPIO_AF7_USART3;
  HAL_GPIO_Init(GPIOD, &GPIO_InitStruct);

  /*Configure GPIO pins : LPS22HB_INT_DRDY_EXTI10_Pin LSM6DSL_INT1_EXTI11_Pin USB_OTG_FS_PWR_EN_Pin ARD_D2_Pin
                           HTS221_DRDY_EXTI15_Pin PMOD_IRQ_EXTI2_Pin */
  GPIO_InitStruct.Pin = LPS22HB_INT_DRDY_EXTI10_Pin|LSM6DSL_INT1_EXTI11_Pin|USB_OTG_FS_PWR_EN_Pin|ARD_D2_Pin
                          |HTS221_DRDY_EXTI15_Pin|PMOD_IRQ_EXTI2_Pin;
  GPIO_InitStruct.Mode = GPIO_MODE_IT_RISING;
  GPIO_InitStruct.Pull = GPIO_NOPULL;
  HAL_GPIO_Init(GPIOD, &GPIO_InitStruct);

  /*Configure GPIO pins : SPBTLE_RF_SPI3_CSN_Pin PMOD_RESET_Pin PMOD_SPI2_SCK_Pin STSAFE_A110_RESET_Pin */
  GPIO_InitStruct.Pin = SPBTLE_RF_SPI3_CSN_Pin|PMOD_RESET_Pin|PMOD_SPI2_SCK_Pin|STSAFE_A110_RESET_Pin;
  GPIO_InitStruct.Mode = GPIO_MODE_OUTPUT_PP;
  GPIO_InitStruct.Pull = GPIO_NOPULL;
  GPIO_InitStruct.Speed = GPIO_SPEED_FREQ_LOW;
  HAL_GPIO_Init(GPIOD, &GPIO_InitStruct);

  /*Configure GPIO pins : VL53L0X_XSHUT_Pin LED3_WIFI__LED4_BLE_Pin */
  GPIO_InitStruct.Pin = VL53L0X_XSHUT_Pin|LED3_WIFI__LED4_BLE_Pin;
  GPIO_InitStruct.Mode = GPIO_MODE_OUTPUT_PP;
  GPIO_InitStruct.Pull = GPIO_NOPULL;
  GPIO_InitStruct.Speed = GPIO_SPEED_FREQ_LOW;
  HAL_GPIO_Init(GPIOC, &GPIO_InitStruct);

  /*Configure GPIO pins : USB_OTG_FS_ID_Pin USB_OTG_FS_DM_Pin USB_OTG_FS_DP_Pin */
  GPIO_InitStruct.Pin = USB_OTG_FS_ID_Pin|USB_OTG_FS_DM_Pin|USB_OTG_FS_DP_Pin;
  GPIO_InitStruct.Mode = GPIO_MODE_AF_PP;
  GPIO_InitStruct.Pull = GPIO_NOPULL;
  GPIO_InitStruct.Speed = GPIO_SPEED_FREQ_VERY_HIGH;
  GPIO_InitStruct.Alternate = GPIO_AF10_OTG_FS;
  HAL_GPIO_Init(GPIOA, &GPIO_InitStruct);

  /*Configure GPIO pins : INTERNAL_SPI3_SCK_Pin INTERNAL_SPI3_MISO_Pin INTERNAL_SPI3_MOSI_Pin */
  GPIO_InitStruct.Pin = INTERNAL_SPI3_SCK_Pin|INTERNAL_SPI3_MISO_Pin|INTERNAL_SPI3_MOSI_Pin;
  GPIO_InitStruct.Mode = GPIO_MODE_AF_PP;
  GPIO_InitStruct.Pull = GPIO_NOPULL;
  GPIO_InitStruct.Speed = GPIO_SPEED_FREQ_VERY_HIGH;
  GPIO_InitStruct.Alternate = GPIO_AF6_SPI3;
  HAL_GPIO_Init(GPIOC, &GPIO_InitStruct);

  /*Configure GPIO pins : PMOD_UART2_CTS_Pin PMOD_UART2_RTS_Pin PMOD_UART2_TX_Pin PMOD_UART2_RX_Pin */
  GPIO_InitStruct.Pin = PMOD_UART2_CTS_Pin|PMOD_UART2_RTS_Pin|PMOD_UART2_TX_Pin|PMOD_UART2_RX_Pin;
  GPIO_InitStruct.Mode = GPIO_MODE_AF_PP;
  GPIO_InitStruct.Pull = GPIO_NOPULL;
  GPIO_InitStruct.Speed = GPIO_SPEED_FREQ_VERY_HIGH;
  GPIO_InitStruct.Alternate = GPIO_AF7_USART2;
  HAL_GPIO_Init(GPIOD, &GPIO_InitStruct);

  /*Configure GPIO pins : ARD_D15_Pin ARD_D14_Pin */
  GPIO_InitStruct.Pin = ARD_D15_Pin|ARD_D14_Pin;
  GPIO_InitStruct.Mode = GPIO_MODE_AF_OD;
  GPIO_InitStruct.Pull = GPIO_PULLUP;
  GPIO_InitStruct.Speed = GPIO_SPEED_FREQ_VERY_HIGH;
  GPIO_InitStruct.Alternate = GPIO_AF4_I2C1;
  HAL_GPIO_Init(GPIOB, &GPIO_InitStruct);

  /* EXTI interrupt init*/
  HAL_NVIC_SetPriority(EXTI9_5_IRQn, 0, 0);
  HAL_NVIC_EnableIRQ(EXTI9_5_IRQn);

  HAL_NVIC_SetPriority(EXTI15_10_IRQn, 0, 0);
  HAL_NVIC_EnableIRQ(EXTI15_10_IRQn);

}

void Error_Handler(void)
{
  __disable_irq();
  while (1)
  {
  }
}
